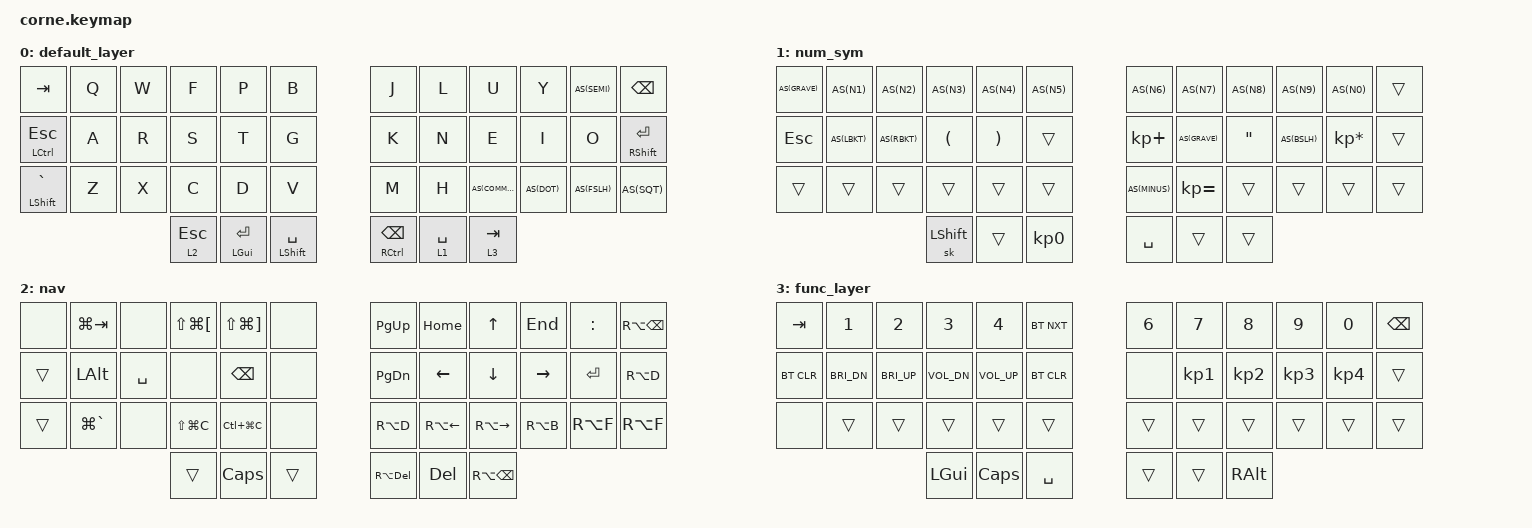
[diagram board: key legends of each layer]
/*
 * Copyright (c) 2020 The ZMK Contributors
 *
 * SPDX-License-Identifier: MIT
 */

#include <behaviors.dtsi>
#include <dt-bindings/zmk/keys.h>
#include <dt-bindings/zmk/bt.h>

#define AS(keycode) &as LS(keycode) keycode     // Autoshift Macro

/ {
	behaviors {
		rst: boot_reset
		{
			compatible = "zmk,behavior-hold-tap";
			label = "Bootloader Tap - Reset Hold";
			#binding-cells = <2>;
			tapping_term_ms = <200>;
            flavor = "balanced";
			bindings = <&sys_reset>, <&bootloader>;
        };

        as: auto_shift {
            compatible = "zmk,behavior-hold-tap";
            label = "AUTO_SHIFT";
            #binding-cells = <2>;
            tapping_term_ms = <183>;
            quick_tap_ms = <0>;
            flavor = "balanced";
            bindings = <&kp>, <&kp>;
        };

        hm: homerow_mods0
		{
			compatible = "zmk,behavior-hold-tap";
			label = "homerow mods";
			#binding-cells = <2>;
			tapping_term_ms = <200>;
            quick-tap-ms = <125>;
            global-quick-tap;
            flavor = "tap-preferred";
			bindings = <&kp>, <&kp>;
        };

        bh: layer_taps
		{
			compatible = "zmk,behavior-hold-tap";
			label = "Layer-Tap";
			#binding-cells = <2>;
			tapping_term_ms = <215>;
            flavor = "tap-preferred";
			bindings = <&mo>, <&kp>;
        };

   	 };
};

/ {
	combos {
		compatible = "zmk,combos";
		combo_backspce {
			timeout-ms = <50>;
			key-positions = <10 11>;
			bindings = <&kp BSPC>;
		};
		combo_tab
		{
			timeout-ms = <35>;
			key-positions = <14 15>;
			bindings = <&kp TAB>;
		};
		combo_minus
		{
			timeout-ms = <30>;
			key-positions = <31 32>;
			bindings = <AS(MINUS)>;
		};
		combo_dollar
		{
			timeout-ms = <30>;
			key-positions = <30 31>;
			bindings = <&kp DLLR>;
		};
		combo_gz
		{
			timeout-ms = <30>;
			key-positions = <25 26>;
			bindings = <&kp LG(Z)>;
		};
		combo_gx
		{
			timeout-ms = <30>;
			key-positions = <26 27>;
			bindings = <&kp LG(X)>;
		};
		combo_gc
		{
			timeout-ms = <40>;
			key-positions = <27 28>;
			bindings = <&kp LG(C)>;
		};
		combo_gv
		{
			timeout-ms = <30>;
			key-positions = <28 29>;
			bindings = <&kp LG(V)>;
		};
		combo_ent
		{
			timeout-ms = <30>;
			key-positions = <20 21>;
			bindings = <&kp RET>;
		};
	};
};

/ {
        keymap {
                compatible = "zmk,keymap";

                default_layer {
// -----------------------------------------------------------------------------------------
// |  TAB |  Q  |  W  |  E  |  R  |  T  |   |  Y  |  U   |  I  |  O  |  P  | BKSP |
// | CTRL |  A  |  S  |  D  |  F  |  G  |   |  H  |  J   |  K  |  L  |  ;  |  '   |
// | SHFT |  Z  |  X  |  C  |  V  |  B  |   |  N  |  M   |  ,  |  .  |  /  | ESC  |
//                    | GUI | LWR | SPC |   | ENT | RSE  | ALT |
                        bindings = <
   &kp TAB         &kp Q &kp W &kp F &kp P &kp B   &kp J &kp L  &kp U     &kp Y   AS(SEMI) &kp BSPC
   &mt LCTRL ESC   &kp A &kp R &kp S &kp T &kp G   &kp K &kp N  &kp E     &kp I   &kp O    &mt RSHFT RET
   &mt LSHFT GRAVE &kp Z &kp X &kp C &kp D &kp V   &kp M &kp H  AS(COMMA) AS(DOT) AS(FSLH) AS(SQT)
                  &lt 2 ESC &mt LGUI RET &mt LSHFT SPACE   &mt RCTRL BSPC &lt 1 SPACE &lt 3 TAB
                        >;
                };

                num_sym {
// -----------------------------------------------------------------------------------------
// |  TAB |  1  |  2  |  3  |  4  |  5  |   |  6  |  7  |  8  |  9  |  0  | BKSP |
// | BTCLR| BT1 | BT2 | BT3 | BT4 | BT5 |   | LFT | DWN |  UP | RGT |     |      |
// | SHFT |     |     |     |     |     |   |     |     |     |     |     |      |
//                    | GUI |     | SPC |   | ENT |     | ALT |
                        bindings = <
   AS(GRAVE) AS(N1)    AS(N2)   AS(N3)   AS(N4)   AS(N5)   AS(N6)       AS(N7)         AS(N8)  AS(N9)    AS(N0) &trans
   &kp ESC   AS(LBKT)  AS(RBKT) &kp LPAR &kp RPAR &trans   &kp KP_PLUS  AS(GRAVE)      &kp DQT AS(BSLH)  &kp KP_ASTERISK &trans
   &trans    &trans    &trans   &trans   &trans   &trans   AS(MINUS) &kp KP_EQUAL   &trans  &trans    &trans &trans
                       &sk LSHFT &trans  &kp KP_N0            &kp SPACE    &trans         &trans
                        >;
                };

                nav {
// -----------------------------------------------------------------------------------------
// |  TAB |  !  |  @  |  #  |  $  |  %  |   |  ^  |  &  |  *  |  (  |  )  | BKSP |
// | CTRL |     |     |     |     |     |   |  -  |  =  |  [  |  ]  |  \  |  `   |
// | SHFT |     |     |     |     |     |   |  _  |  +  |  {  |  }  | "|" |  ~   |
//                    | GUI |     | SPC |   | ENT |     | ALT |
                        bindings = <
    &none    &kp LG(TAB)   &none     &kp LS(LG(LBKT)) &kp LS(LG(RBKT)) &none   &kp PG_UP &kp HOME     &kp UP        &kp END   &kp COLON &kp RA(BSPC)
    &trans   &kp LALT      &kp SPACE &none            &kp BSPC         &none   &kp PG_DN &kp LEFT     &kp DOWN      &kp RIGHT &kp RET   &kp RA(D)
    &trans   &kp LG(GRAVE) &none     &kp LS(LG(C))    &kp LC(LG(C))    &none   &kp RA(D) &kp RA(LEFT) &kp RA(RIGHT) &kp RA(B) &kp RA(F) &kp RA(F)
                           &trans    &kp CAPS &trans     &kp RA(DEL)  &kp DEL &kp RA(BSPC)
                        >;
                };

                func_layer {
// -----------------------------------------------------------------------------------------
// |  TAB |  1  |  2  |  3  |  4  |  5  |   |  6  |  7  |  8  |  9  |  0  | BKSP |
// | BTCLR| BT1 | BT2 | BT3 | BT4 | BT5 |   | LFT | DWN |  UP | RGT |     |      |
// | SHFT |     |     |     |     |     |   |     |     |     |     |     |      |
//                    | GUI |     | SPC |   | ENT |     | ALT |
                        bindings = <
   &kp TAB    &kp N1       &kp N2       &kp N3       &kp N4        &bt BT_NXT         &kp N6   &kp N7   &kp N8 &kp N9    &kp N0 &kp BSPC
   &bt BT_CLR &kp C_BRI_DN &kp C_BRI_UP &kp C_VOL_DN &kp C_VOL_UP  &bt BT_CLR    &none  &kp KP_N1   &kp KP_N2 &kp KP_N3 &kp KP_N4  &trans
   &none &trans       &trans       &trans       &trans       &trans         &trans   &trans   &trans &trans    &trans &trans
                          	        &kp LGUI     &kp CAPS    &kp SPACE          &trans &trans   &kp RALT
                        >;
                };
        };
};
